AUTOSAR XML (schema 00046)
package /TigerDetectionSW
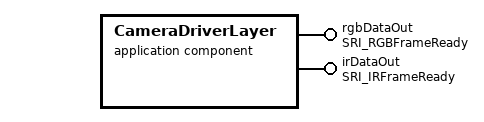
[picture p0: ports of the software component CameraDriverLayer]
  application sw component type CameraDriverLayer
    provide port rgbDataOut: provided-interface=SRI_RGBFrameReady
    provide port irDataOut: provided-interface=SRI_IRFrameReady
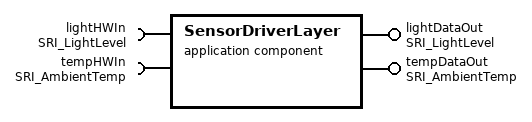
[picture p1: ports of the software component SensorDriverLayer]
  application sw component type SensorDriverLayer
    provide port lightDataOut: provided-interface=SRI_LightLevel
    provide port tempDataOut: provided-interface=SRI_AmbientTemp
    require port lightHWIn: required-interface=SRI_LightLevel
    require port tempHWIn: required-interface=SRI_AmbientTemp
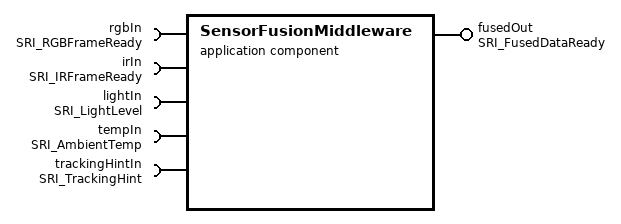
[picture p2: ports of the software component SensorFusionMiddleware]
  application sw component type SensorFusionMiddleware
    provide port fusedOut: provided-interface=SRI_FusedDataReady
    5 x require port:
      rgbIn: required-interface=SRI_RGBFrameReady
      irIn: required-interface=SRI_IRFrameReady
      lightIn: required-interface=SRI_LightLevel
      tempIn: required-interface=SRI_AmbientTemp
      trackingHintIn: required-interface=SRI_TrackingHint
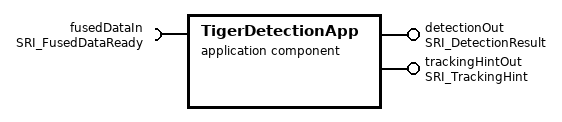
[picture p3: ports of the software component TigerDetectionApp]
  application sw component type TigerDetectionApp
    provide port detectionOut: provided-interface=SRI_DetectionResult
    provide port trackingHintOut: provided-interface=SRI_TrackingHint
    require port fusedDataIn: required-interface=SRI_FusedDataReady
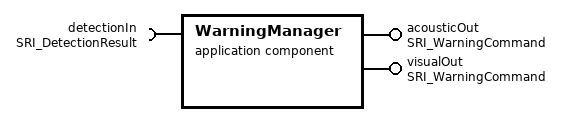
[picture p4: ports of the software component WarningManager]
  application sw component type WarningManager
    provide port acousticOut: provided-interface=SRI_WarningCommand
    provide port visualOut: provided-interface=SRI_WarningCommand
    require port detectionIn: required-interface=SRI_DetectionResult
  composition sw component type TigerDetectionComposition
    5 x component:
      CameraDriverLayer_Instance: type=CameraDriverLayer
      SensorDriverLayer_Instance: type=SensorDriverLayer
      SensorFusionMiddleware_Instance: type=SensorFusionMiddleware
      TigerDetectionApp_Instance: type=TigerDetectionApp
      WarningManager_Instance: type=WarningManager
    connect CameraDriverLayer_Instance.rgbDataOut -> SensorFusionMiddleware_Instance.rgbIn
    connect CameraDriverLayer_Instance.irDataOut -> SensorFusionMiddleware_Instance.irIn
    connect SensorDriverLayer_Instance.lightDataOut -> SensorFusionMiddleware_Instance.lightIn
    connect SensorDriverLayer_Instance.tempDataOut -> SensorFusionMiddleware_Instance.tempIn
    connect SensorFusionMiddleware_Instance.fusedOut -> TigerDetectionApp_Instance.fusedDataIn
    connect TigerDetectionApp_Instance.detectionOut -> WarningManager_Instance.detectionIn
    connect TigerDetectionApp_Instance.trackingHintOut -> SensorFusionMiddleware_Instance.trackingHintIn
